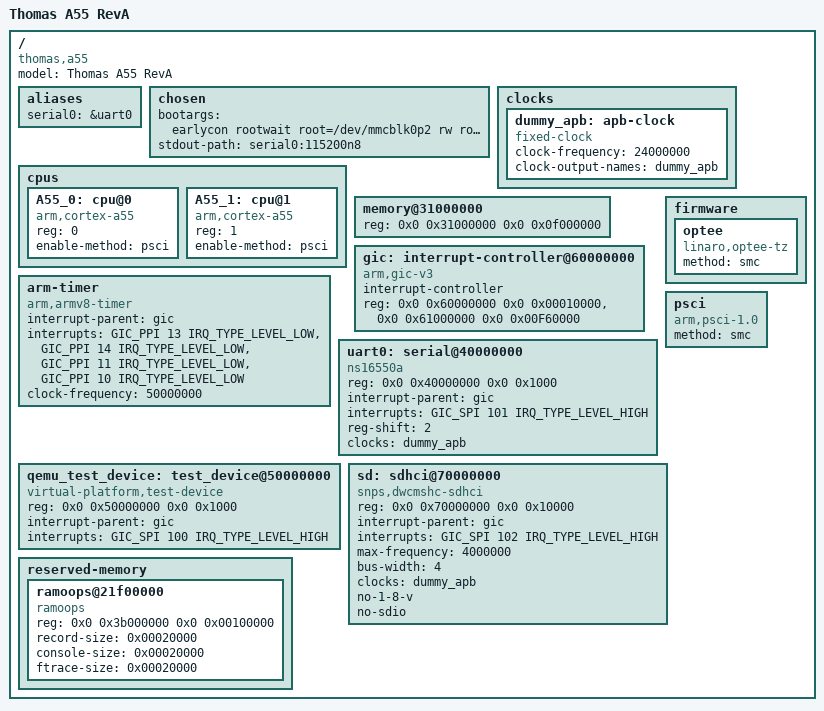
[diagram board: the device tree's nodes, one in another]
// SPDX-License-Identifier: GPL-2.0
/*
 * Thomas-a55
 *
 */

#include <dt-bindings/interrupt-controller/irq.h>
#include <dt-bindings/interrupt-controller/arm-gic.h>

/dts-v1/;

/ {

	model = "Thomas A55 RevA";
	compatible = "thomas,a55";
	#address-cells = <2>;
	#size-cells = <2>;

	aliases {
		serial0 = &uart0;
	};

	chosen {
		bootargs = "earlycon rootwait root=/dev/mmcblk0p2 rw rootfstype=ext4 crashkernel=0x02000000@0x36000000"; /*\
			pstore.backend=pstore_blk pstore_blk.blkdev=/dev/mmcblk0p3 pstore_blk.kmsg_size=64 pstore_blk.best_effort=y";*/
		stdout-path = "serial0:115200n8";
	};

	clocks {
		dummy_apb: apb-clock {
			compatible = "fixed-clock";
			clock-frequency = <24000000>;
			clock-output-names = "dummy_apb";
			#clock-cells = <0>;
		};
	};

	cpus {
		#address-cells = <1>;
		#size-cells = <0>;

		A55_0: cpu@0 {
			device_type = "cpu";
			compatible = "arm,cortex-a55";
			reg = <0>;
			enable-method = "psci";
		};

		A55_1: cpu@1 {
			device_type = "cpu";
			compatible = "arm,cortex-a55";
			reg = <1>;
			enable-method = "psci";
		};
	};

	memory@31000000 {
		device_type = "memory";
		reg = <0x0 0x31000000 0x0 0x0f000000>;
	};

	gic: interrupt-controller@60000000 {
		compatible = "arm,gic-v3";
		#interrupt-cells = <3>;
		#address-cells = <1>;
		#size-cells = <1>;
		interrupt-controller;
		reg = <0x0 0x60000000 0x0 0x00010000>,	// GICD
		      <0x0 0x61000000 0x0 0x00F60000>;	// GICR
	};

	arm-timer {
		compatible = "arm,armv8-timer";
		interrupt-parent = <&gic>;
		interrupts = <GIC_PPI 13 IRQ_TYPE_LEVEL_LOW>,
			     <GIC_PPI 14 IRQ_TYPE_LEVEL_LOW>,
			     <GIC_PPI 11 IRQ_TYPE_LEVEL_LOW>,
			     <GIC_PPI 10 IRQ_TYPE_LEVEL_LOW>;
		clock-frequency = <50000000>;
	};

	uart0: serial@40000000 {
		compatible = "ns16550a";
		reg = <0x0 0x40000000 0x0 0x1000>;
		interrupt-parent = <&gic>;
		interrupts = <GIC_SPI 101 IRQ_TYPE_LEVEL_HIGH>;
		reg-shift = <2>;
		clocks = <&dummy_apb>;
	};

	qemu_test_device: test_device@50000000 {
		compatible = "virtual-platform,test-device";
		reg = <0x0 0x50000000 0x0 0x1000>;
		interrupt-parent = <&gic>;
		interrupts = <GIC_SPI 100 IRQ_TYPE_LEVEL_HIGH>;
	};

	firmware {
		optee: optee {
			compatible = "linaro,optee-tz";
			method = "smc";
			status = "okay";
		};
	};

	psci {
		compatible = "arm,psci-1.0";
		method = "smc";
	};

	sd: sdhci@70000000 {
		compatible = "snps,dwcmshc-sdhci";
		reg = <0x0 0x70000000 0x0 0x10000>;
		interrupt-parent = <&gic>;
		interrupts = <GIC_SPI 102 IRQ_TYPE_LEVEL_HIGH>;
		max-frequency = <4000000>;
		bus-width = <4>;
		clocks = <&dummy_apb>;
		clock-names = "core";
		no-1-8-v;
		no-sdio;
		status = "okay";
	};

	reserved-memory {
		#address-cells = <2>;
		#size-cells = <2>;
		ranges;

		ramoops@21f00000 {
			compatible = "ramoops";
			reg = <0x0 0x3b000000 0x0 0x00100000>;
			record-size     = <0x00020000>;
			console-size    = <0x00020000>;
			ftrace-size     = <0x00020000>;
		};
	};



};
